# MK50D10 register map
Vendor: Freescale Semiconductor, Inc.; Series: Kinetis_K; File version: 1.6
CPU: CM4 r0p1, little endian, no MPU, no FPU, VTOR, 4 interrupt priority bits
Registers are 8-bit, read-write, reset 0x0 unless marked. A register's access mark holds for its fields unless they carry their own. Offsets are from the block's base; [hi:lo] are bit positions; 'fields as' and 'values as' point back to an identical list.

## TRIAMP0 — Trans-Impedance Amplifier
Base 0x400F8000; register names take the prefix TRIAMP0_
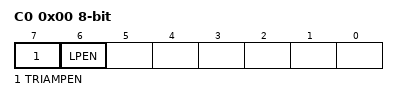
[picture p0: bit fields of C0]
0x00 C0 — Control Register 0
  [7] TRIAMPEN — TRIAMP Enable
    0=The amplifier is disabled and not powered; 1=TRIAMP system is enabled. In this mode, the amplifier is powered and enabled.
  [6] LPEN — Low-Power Enable
    0=High-speed mode selected. In this mode, TRIAMP has faster slew rate and unity gain bandwidth performance with higher current consumption.; 1=Low-power mode selected. In this mode, TRIAMP has lower current consumption with slower slew rate and unity gain bandwidth performance.

## TRIAMP1 — Trans-Impedance Amplifier
Base 0x400F8800; register names take the prefix TRIAMP1_
Registers as TRIAMP0.

## GPIOA — General Purpose Input/Output
Base 0x400FF000; register names take the prefix GPIOA_
0x00 PDOR 32-bit — Port Data Output Register
  [31:0] PDO — Port Data Output
    0=Logic level 0 is driven on pin, provided pin is configured for general-purpose output; 1=Logic level 1 is driven on pin, provided pin is configured for general-purpose output
0x04 PSOR 32-bit wo — Port Set Output Register
  [31:0] PTSO — Port Set Output
    0=Corresponding bit in PDORn does not change; 1=Corresponding bit in PDORn is set to logic 1
0x08 PCOR 32-bit wo — Port Clear Output Register
  [31:0] PTCO — Port Clear Output
    0=Corresponding bit in PDORn does not change; 1=Corresponding bit in PDORn is cleared to logic 0
0x0C PTOR 32-bit wo — Port Toggle Output Register
  [31:0] PTTO — Port Toggle Output
    0=Corresponding bit in PDORn does not change; 1=Corresponding bit in PDORn is set to the inverse of its existing logic state
0x10 PDIR 32-bit ro — Port Data Input Register
  [31:0] PDI — Port Data Input
    0=Pin logic level is logic 0, or is not configured for use by digital function; 1=Pin logic level is logic 1
0x14 PDDR 32-bit — Port Data Direction Register
  [31:0] PDD — Port Data Direction
    0=Pin is configured as general-purpose input, for the GPIO function; 1=Pin is configured as general-purpose output, for the GPIO function

## GPIOB — General Purpose Input/Output
Base 0x400FF040; register names take the prefix GPIOB_
Registers as GPIOA.

## GPIOC — General Purpose Input/Output
Base 0x400FF080; register names take the prefix GPIOC_
Registers as GPIOA.

## GPIOD — General Purpose Input/Output
Base 0x400FF0C0; register names take the prefix GPIOD_
Registers as GPIOA.

## GPIOE — General Purpose Input/Output
Base 0x400FF100; register names take the prefix GPIOE_
Registers as GPIOA.

## SysTick — System timer
Base 0xE000E010; register names take the prefix SYST_
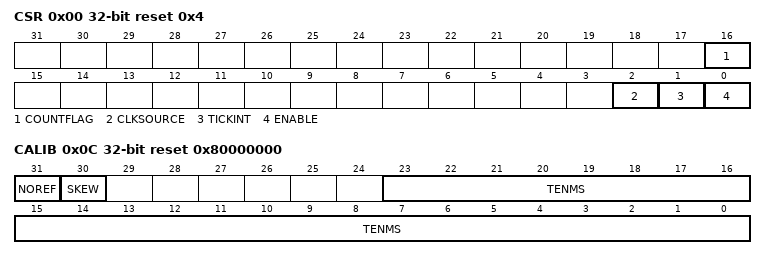
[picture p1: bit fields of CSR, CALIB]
0x00 CSR 32-bit reset 0x4 — SysTick Control and Status Register
  [16] COUNTFLAG
  [2] CLKSOURCE
    0=external clock; 1=processor clock
  [1] TICKINT
    0=counting down to 0 does not assert the SysTick exception request; 1=counting down to 0 asserts the SysTick exception request
  [0] ENABLE
    0=counter disabled; 1=counter enabled
0x04 RVR 32-bit — SysTick Reload Value Register
  [23:0] RELOAD — Value to load into the SysTick Current Value Register when the counter reaches 0
0x08 CVR 32-bit — SysTick Current Value Register
  [23:0] CURRENT — Current value at the time the register is accessed
0x0C CALIB 32-bit ro reset 0x80000000 — SysTick Calibration Value Register
  [31] NOREF
    0=The reference clock is provided; 1=The reference clock is not provided
  [30] SKEW
    0=10ms calibration value is exact; 1=10ms calibration value is inexact, because of the clock frequency
  [23:0] TENMS — Reload value to use for 10ms timing

## MCM — Core Platform Miscellaneous Control Module
Base 0xE0080000; register names take the prefix MCM_
0x08 PLASC 16-bit ro reset 0x1F — Crossbar Switch (AXBS) Slave Configuration
  [7:0] ASC — Each bit in the ASC field indicates whether there is a corresponding connection to the crossbar switch's slave input port.
    0=A bus slave connection to AXBS input port n is absent; 1=A bus slave connection to AXBS input port n is present
0x0A PLAMC 16-bit ro reset 0x3F — Crossbar Switch (AXBS) Master Configuration
  [7:0] AMC — Each bit in the AMC field indicates whether there is a corresponding connection to the AXBS master input port.
    0=A bus master connection to AXBS input port n is absent; 1=A bus master connection to AXBS input port n is present
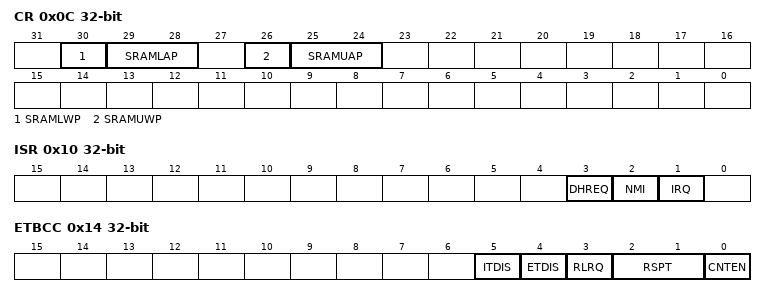
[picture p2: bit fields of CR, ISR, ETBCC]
0x0C CR 32-bit — Control Register
  [30] SRAMLWP — SRAM_L Write Protect
  [29:28] SRAMLAP — SRAM_L arbitration priority
    0=Round robin; 1=Special round robin (favors SRAM backoor accesses over the processor); 2=Fixed priority. Processor has highest, backdoor has lowest; 3=Fixed priority. Backdoor has highest, processor has lowest
  [26] SRAMUWP — SRAM_U write protect
  [25:24] SRAMUAP — SRAM_U arbitration priority
    values as SRAMLAP
0x10 ISR 32-bit — Interrupt Status Register
  [3] DHREQ ro — Debug Halt Request Indicator
    0=No debug halt request; 1=Debug halt request initiated
  [2] NMI — Non-maskable Interrupt Pending
    0=No pending NMI; 1=Due to the ETB counter expiring, an NMI is pending
  [1] IRQ — Normal Interrupt Pending
    0=No pending interrupt; 1=Due to the ETB counter expiring, a normal interrupt is pending
0x14 ETBCC 32-bit — ETB Counter Control register
  [5] ITDIS — ITM-To-TPIU Disable
    0=ITM-to-TPIU trace path enabled; 1=ITM-to-TPIU trace path disabled
  [4] ETDIS — ETM-To-TPIU Disable
    0=ETM-to-TPIU trace path enabled; 1=ETM-to-TPIU trace path disabled
  [3] RLRQ — Reload Request
    0=No effect; 1=Clears pending debug halt, NMI, or IRQ interrupt requests
  [2:1] RSPT — Response Type
    0=No response when the ETB count expires; 1=Generate a normal interrupt when the ETB count expires; 2=Generate an NMI when the ETB count expires; 3=Generate a debug halt when the ETB count expires
  [0] CNTEN — Counter Enable
    0=ETB counter disabled; 1=ETB counter enabled
0x18 ETBRL 32-bit — ETB Reload register
  [10:0] RELOAD — Byte Count Reload Value
0x1C ETBCNT 32-bit ro — ETB Counter Value register
  [10:0] COUNTER — Byte Count Counter Value
0x30 PID 32-bit — Process ID register
  [7:0] PID — M0_PID And M1_PID For MPU
